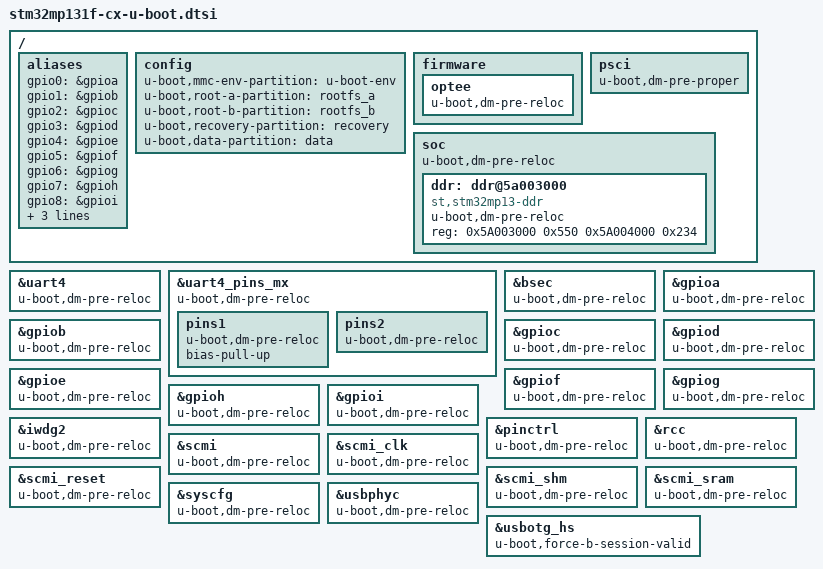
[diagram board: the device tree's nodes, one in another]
// SPDX-License-Identifier: GPL-2.0+ OR BSD-3-Clause
/*
* Copyright : STMicroelectronics 2020
*/
#include <dt-bindings/gpio/gpio.h>

/ {
	aliases {
		gpio0 = &gpioa;
		gpio1 = &gpiob;
		gpio2 = &gpioc;
		gpio3 = &gpiod;
		gpio4 = &gpioe;
		gpio5 = &gpiof;
		gpio6 = &gpiog;
		gpio7 = &gpioh;
		gpio8 = &gpioi;
		pinctrl0 = &pinctrl;

		mmc1 = &sdmmc2;
		usb0 = &usbotg_hs;
	};

	config {
		// Map partition labels into u-boot
		u-boot,mmc-env-partition = "u-boot-env";
		u-boot,root-a-partition = "rootfs_a";
		u-boot,root-b-partition = "rootfs_b";
		u-boot,recovery-partition = "recovery";
		u-boot,data-partition = "data";
	};

	firmware {
		optee {
			u-boot,dm-pre-reloc;
		};
	};

	/* need PSCI for sysreset during board_f */
	psci {
		u-boot,dm-pre-proper;
	};

	soc {
		u-boot,dm-pre-reloc;

		ddr: ddr@5a003000 {
			u-boot,dm-pre-reloc;

			compatible = "st,stm32mp13-ddr";

			reg = <0x5A003000 0x550
			0x5A004000 0x234>;

			status = "okay";
		};
	};
};

&uart4 {
	u-boot,dm-pre-reloc;
};

&uart4_pins_mx {
	u-boot,dm-pre-reloc;
	pins1 {	/* UART4_RX */
		u-boot,dm-pre-reloc;
		/* pull-up on rx to avoid floating level */
		bias-pull-up;
	};
	pins2 {
		u-boot,dm-pre-reloc;
	};
};

&bsec {
	u-boot,dm-pre-reloc;
};

&gpioa {
	u-boot,dm-pre-reloc;
};

&gpiob {
	u-boot,dm-pre-reloc;
};

&gpioc {
	u-boot,dm-pre-reloc;
};

&gpiod {
	u-boot,dm-pre-reloc;
};

&gpioe {
	u-boot,dm-pre-reloc;
};

&gpiof {
	u-boot,dm-pre-reloc;
};

&gpiog {
	u-boot,dm-pre-reloc;
};

&gpioh {
	u-boot,dm-pre-reloc;
};

&gpioi {
	u-boot,dm-pre-reloc;
};

&iwdg2 {
	u-boot,dm-pre-reloc;
};

&pinctrl {
	u-boot,dm-pre-reloc;
};

&rcc {
	u-boot,dm-pre-reloc;
};

&scmi {
	u-boot,dm-pre-reloc;
};

&scmi_clk {
	u-boot,dm-pre-reloc;
};

&scmi_reset {
	u-boot,dm-pre-reloc;
};

&scmi_shm {
	u-boot,dm-pre-reloc;
};

&scmi_sram {
	u-boot,dm-pre-reloc;
};

&syscfg {
	u-boot,dm-pre-reloc;
};

&usbphyc {
	/* stm32-usbphyc-clk = ck_usbo_48m is a source clock of RCC CCF */
	u-boot,dm-pre-reloc;
};

&usbotg_hs {
	u-boot,force-b-session-valid;
};
